# STM32WBA62 register map
File version: 1.1
CPU: CM33 r0p1, little endian, MPU, FPU, 4 interrupt priority bits
Registers are 32-bit, read-write, reset 0x0 unless marked. A register's access mark holds for its fields unless they carry their own. Offsets are from the block's base; [hi:lo] are bit positions; {n}, {i} and the like mark numbered series.

## FLASH — FLASH register block
Base 0x40022000
Same registers: SEC_FLASH 0x50022000
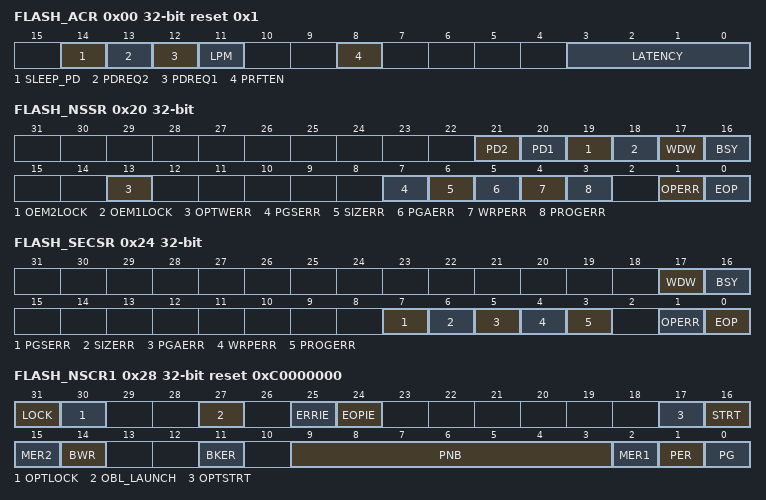
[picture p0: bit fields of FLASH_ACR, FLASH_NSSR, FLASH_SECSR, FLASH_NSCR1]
0x00 FLASH_ACR reset 0x1 — FLASH access control register
  [14] SLEEP_PD — Flash memory power-down mode during Sleep mode
    0=Flash in idle mode during Sleep mode; 1=Flash in power-down mode during Sleep mode
  [13] PDREQ2 — Bank 2 power-down mode request
    0=No request for bank 2 to enter power-down mode; 1=Bank 2 requested to enter power-down mode'
  [12] PDREQ1 — Bank 1 power-down mode request
    0=No request for bank 1 to enter power-down mode; 1=Bank 1 requested to enter power-down mode
  [11] LPM — Low-power read mode
    0=Flash not in low-power read mode; 1=Flash in low-power read mode
  [8] PRFTEN — Prefetch enable
    0=Prefetch disabled; 1=Prefetch enabled
  [3:0] LATENCY
    0=Zero wait state; 1=One wait state; 2=Two wait states; 15=Fifteen wait states
0x08 FLASH_NSKEYR wo — FLASH key register
  [31:0] NSKEY — Flash memory nonsecure key
0x0C FLASH_SECKEYR wo — FLASH secure key register
  [31:0] SECKEY — Flash memory secure key
0x10 FLASH_OPTKEYR wo — FLASH option key register
  [31:0] OPTKEY — Option byte key
0x18 FLASH_PDKEY1R wo — FLASH bank 1 power-down key register
  [31:0] PDKEY — Bank 1 power-down key
0x1C FLASH_PDKEY2R wo — FLASH bank 2 power-down key register
  [31:0] PDKEY — Bank 2 power-down key
0x20 FLASH_NSSR (reset mask 0xFFF0FFFF) — FLASH status register
  [21] PD2 ro — Bank 2 in power-down mode
  [20] PD1 ro — Bank 1 in power-down mode
  [19] OEM2LOCK ro — OEM2 key RDP lock
  [18] OEM1LOCK ro — OEM1 key RDP lock
  [17] WDW ro — nonsecure wait data to write
  [16] BSY ro — nonsecure busy
  [13] OPTWERR — Option write error
  [7] PGSERR — nonsecure programming sequence error
  [6] SIZERR — nonsecure size error
  [5] PGAERR — nonsecure programming alignment error
  [4] WRPERR — nonsecure write protection error
  [3] PROGERR — nonsecure programming error
  [1] OPERR — nonsecure operation error
  [0] EOP — nonsecure end of operation
0x24 FLASH_SECSR — FLASH secure status register
  [17] WDW ro — Secure wait data to write
  [16] BSY ro — Secure busy
  [7] PGSERR — Secure programming sequence error
  [6] SIZERR — Secure size error
  [5] PGAERR — Secure programming alignment error
  [4] WRPERR — Secure write protection error
  [3] PROGERR — Secure programming error
  [1] OPERR — Secure operation error
  [0] EOP — Secure end of operation
0x28 FLASH_NSCR1 reset 0xC0000000 — FLASH control register
  [31] LOCK — nonsecure lock
  [30] OPTLOCK — Option lock
  [27] OBL_LAUNCH — Force the option byte loading
    0=Option byte loading complete; 1=Option byte loading requested
  [25] ERRIE — nonsecure error interrupt enable
    0=nonsecure OPERR error interrupt disabled; 1=nonsecure OPERR error interrupt enabled
  [24] EOPIE — nonsecure end of operation interrupt enable
    0=nonsecure EOP Interrupt disabled; 1=nonsecure EOP Interrupt enabled
  [17] OPTSTRT — Options modification start
  [16] STRT — nonsecure operation start
  [15] MER2 — nonsecure flash bank 2 erase
  [14] BWR — nonsecure burst write programming mode
  [11] BKER — Bank selection for nonsecure page erase
    0=Bank 1 selected for nonsecure page erase; 1=Bank 2 selected for nonsecure page erase
  [9:3] PNB — nonsecure bank page number selection
    0=page 0; 1=page 1; 63=page 63; 127=page 127
  [2] MER1 — nonsecure flash bank 1 erase
  [1] PER — nonsecure page erase
    0=nonsecure page erase disabled; 1=nonsecure page erase enabled
  [0] PG — nonsecure programming
    0=nonsecure flash programming disabled; 1=nonsecure flash programming enabled
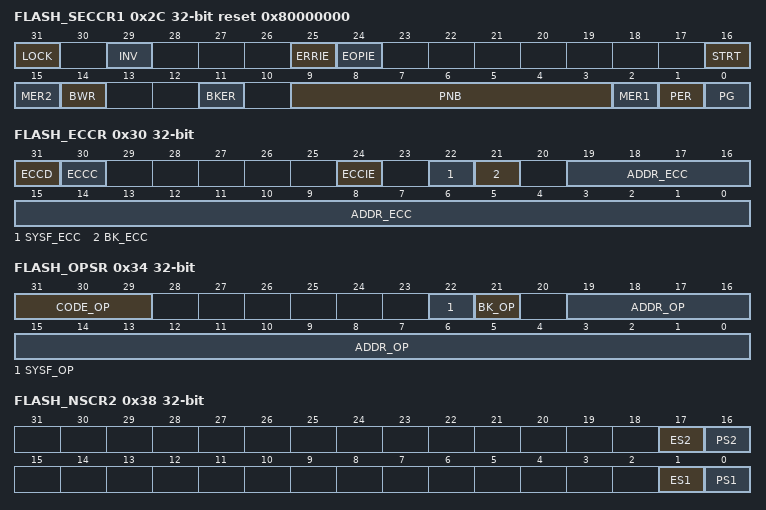
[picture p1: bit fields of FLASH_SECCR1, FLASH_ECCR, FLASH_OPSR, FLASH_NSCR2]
0x2C FLASH_SECCR1 reset 0x80000000 — FLASH secure control register
  [31] LOCK — Secure lock
  [29] INV — Flash memory security state invert
  [25] ERRIE — Secure error interrupt enable
    0=Secure OPERR error interrupt disabled; 1=Secure OPERR error interrupt enabled
  [24] EOPIE — Secure End of operation interrupt enable
    0=Secure EOP Interrupt disabled; 1=Secure EOP Interrupt enabled
  [16] STRT — Secure start
  [15] MER2 — Secure flash bank 2 erase
  [14] BWR — Secure burst write programming mode
  [11] BKER — Bank selection for secure page erase
    0=Bank 1 selected for secure page erase; 1=Bank 2 selected for secure page erase
  [9:3] PNB — Secure bank page number selection
    0=page 0; 1=page 1; 63=page 63; 127=page 127
  [2] MER1 — Secure flash bank 1 erase
  [1] PER — Secure page erase
    0=Secure page erase disabled; 1=Secure page erase enabled
  [0] PG — Secure programming
    0=Secure flash programming disabled; 1=Secure flash programming enabled
0x30 FLASH_ECCR — FLASH ECC register
  [31] ECCD — ECC detection
  [30] ECCC — ECC correction
  [24] ECCIE — ECC correction interrupt enable
    0=ECCC interrupt disabled; 1=ECCC interrupt enabled
  [22] SYSF_ECC ro — System flash memory ECC fail
  [21] BK_ECC ro — bank ECC fail
    0=Bank 1; 1=Bank 2
  [19:0] ADDR_ECC ro — ECC fail address
0x34 FLASH_OPSR ro (reset mask 0xF000000) — FLASH operation status register
  [31:29] CODE_OP — Flash memory operation code
    0=No flash operation interrupted by previous reset; 1=Single write operation interrupted; 2=Burst write operation interrupted; 3=Page erase operation interrupted; 4=Bank erase operation interrupted; 5=Mass erase operation interrupted; 6=Option change operation interrupted
  [22] SYSF_OP — Operation in system flash memory interrupted
  [21] BK_OP — Operation in bank interrupted
    0=Bank 1; 1=Bank 2
  [19:0] ADDR_OP — Interrupted operation address
0x38 FLASH_NSCR2 — FLASH control 2 register
  [17] ES2 — Bank 2 nonsecure erase suspend request
    0=Bank 2 nonsecure erase suspend disabled; 1=Bank 2 nonsecure erase suspend requested (enabled)
  [16] PS2 — Bank 2 nonsecure program suspend request
    0=Bank 2 nonsecure program suspend disabled; 1=Bank 2 nonsecure program suspend requested (enabled)
  [1] ES1 — Bank 1 nonsecure erase suspend request
    0=Bank 1 nonsecure erase suspend disabled; 1=Bank 1 nonsecure erase suspend requested (enabled)
  [0] PS1 — Bank 1 nonsecure program suspend request
    0=Bank 1 nonsecure program suspend disabled; 1=Bank 1 nonsecure program suspend requested (enabled)
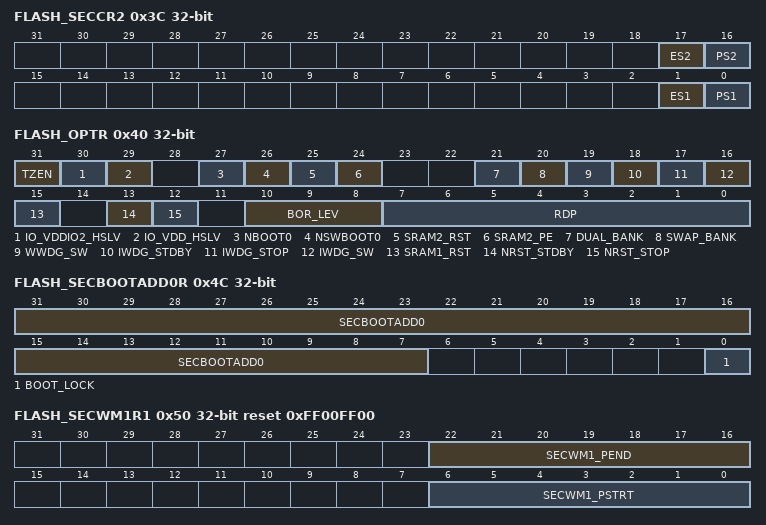
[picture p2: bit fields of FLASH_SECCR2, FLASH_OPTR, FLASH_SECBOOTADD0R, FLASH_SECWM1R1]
0x3C FLASH_SECCR2 — FLASH secure control 2 register
  [17] ES2 — Bank 2 secure erase suspend request
    0=Bank 2 secure erase suspend disabled; 1=Bank 2 secure erase suspend requested (enabled)
  [16] PS2 — Bank 2 secure program suspend request
    0=Bank 2 secure program suspend disabled; 1=Bank 2 secure program suspend requested (enabled)
  [1] ES1 — Bank 1 secure erase suspend request
    0=Bank 1 secure erase suspend disabled; 1=Bank 1 secure erase suspend requested (enabled)
  [0] PS1 — Bank 1 secure program suspend request
    0=Bank 1 secure program suspend disabled; 1=Bank 1 secure program suspend requested (enabled)
0x40 FLASH_OPTR reset not defined — FLASH option register
  [31] TZEN — Global TrustZone security enable
    0=Global TrustZone security disabled; 1=Global TrustZone security enabled
  [30] IO_VDDIO2_HSLV — High-speed IO at low Vless thansub DDIO2less than/sub voltage configuration
    0=High-speed IO at low Vless thansub DDIO2less than/sub voltage disabled; 1=High-speed IO at low Vless thansub DDIO2less than/sub voltage enabling in GPIO peripheral allowed (Vless thansub DDIO2less than/sub voltage must be below, refer to datasheet
  [29] IO_VDD_HSLV — High-speed IO at low Vless thansub DDless than/sub voltage configuration
    0=High-speed IO at low Vless thansub DDless than/sub voltage disabled; 1=High-speed IO at low Vless thansub DDless than/sub voltage enabling in GPIO peripheral allowed (Vless thansub DDless than/sub voltage must be below, refer to datasheet)
  [27] NBOOT0 — NBOOT0 option bit
    0=NBOOT0 = 0; 1=NBOOT0 = 1
  [26] NSWBOOT0 — Software BOOT0
    0=BOOT0 taken from the option bit NBOOT0; 1=BOOT0 taken from PH3/BOOT0 pin
  [25] SRAM2_RST — SRAM2 erase when system reset
    0=SRAM2 erased when a system reset occurs; 1=SRAM2 not erased when a system reset occurs
  [24] SRAM2_PE — SRAM2 parity check enable
    0=SRAM2 parity check enabled; 1=SRAM2 parity check disabled
  [21] DUAL_BANK — Dual-bank on 1-Mbyte flash memory
    0=Single-bank flash with contiguous addresses in bank 1; 1=Dual-bank flash with contiguous addresses
  [20] SWAP_BANK
    0=Banks not swapped, Main memory bank 1 base address offset 0, bank 2 base address offset 0x10 0000; 1=Banks swapped, Main memory bank 1 base address offset 0x10 0000, bank 2 base address offset 0
  [19] WWDG_SW — Window watchdog selection
    0=Hardware window watchdog selected; 1=Software window watchdog selected
  [18] IWDG_STDBY — Independent watchdog counter freeze in Standby mode
    0=Independent watchdog counter frozen in Standby mode; 1=Independent watchdog counter running in Standby mode
  [17] IWDG_STOP — Independent watchdog counter freeze in Stop mode
    0=Independent watchdog counter frozen in Stop mode; 1=Independent watchdog counter running in Stop mode
  [16] IWDG_SW — Independent watchdog enable selection
    0=Hardware mode, independent watchdog started automatically be hardware on reset selected; 1=Software mode, independent watchdog started by software command selected
  [15] SRAM1_RST — SRAM1 erase upon system reset
    0=SRAM1erased when a system reset occurs; 1=SRAM1 not erased when a system reset occurs
  [13] NRST_STDBY — Reset generation in Standby mode
    0=Reset generated when entering the Standby mode; 1=No reset generated when entering the Standby mode
  [12] NRST_STOP — Reset generation in Stop mode
    0=Reset generated when entering the Stop mode; 1=No reset generated when entering the Stop mode
  [10:8] BOR_LEV — BOR reset level
    0=BOR level 0 (reset level threshold around 1; {v}=BOR level {v} (reset level threshold around 2 (v=1..4)
  [7:0] RDP — Readout protection level
    170=Level 0 (readout protection not active); 85=Level 0; 204=Level 2 (chip readout protection active)
0x44 FLASH_NSBOOTADD0R reset 0xF (reset mask 0xF) — FLASH boot address 0 register
  [31:7] NSBOOTADD0 — nonsecure boot base address 0
0x48 FLASH_NSBOOTADD1R reset 0xF (reset mask 0xF) — FLASH boot address 1 register
  [31:7] NSBOOTADD1 — nonsecure boot address 1
0x4C FLASH_SECBOOTADD0R reset not defined — FLASH secure boot address 0 register
  [31:7] SECBOOTADD0 — Secure boot base address 0
  [0] BOOT_LOCK
0x50 FLASH_SECWM1R1 reset 0xFF00FF00 (reset mask 0xFF00FF00) — FLASH bank 1 secure watermark register 1
  [22:16] SECWM1_PEND — Bank 1 end page of secure area
  [6:0] SECWM1_PSTRT — Bank 1 start page of secure area
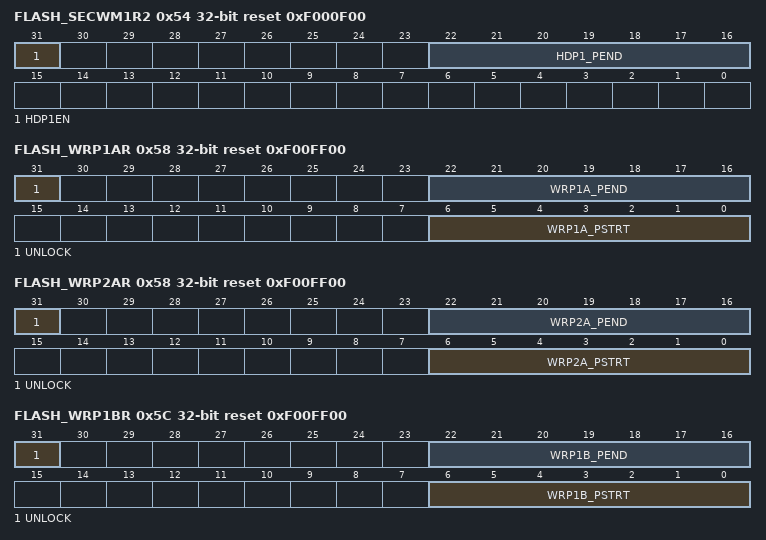
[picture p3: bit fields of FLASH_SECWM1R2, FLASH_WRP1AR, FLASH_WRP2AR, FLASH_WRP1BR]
0x54 FLASH_SECWM1R2 reset 0xF000F00 (reset mask 0xF000F00) — FLASH bank 1 secure watermark register 2
  [31] HDP1EN — Bank 1 secure Hide protection area enable
    0=No bank 1 secure HDP area; 1=Bank 1 secure HDP area enabled
  [22:16] HDP1_PEND — Bank 1 end page of secure hide protection area
0x58 FLASH_WRP1AR reset 0xF00FF00 (reset mask 0xF00FF00) — FLASH WRP bank 1 area A address register
  [31] UNLOCK — WPR bank 1 area A unlock
    0=WRP bank 1 area A start and end pages locked; 1=WRP bank 1 area A start and end pages unlocked
  [22:16] WRP1A_PEND — WPR bank 1 area A end page
  [6:0] WRP1A_PSTRT — WPR bank 1 area A start page
0x58 FLASH_WRP2AR reset 0xF00FF00 (reset mask 0xF00FF00) (alternate view of FLASH_WRP1AR) — FLASH WRP bank 2 area A address register
  [31] UNLOCK — WPR bank 2 area A unlock
    0=WRP bank 2 area A start and end pages locked; 1=WRP bank 2 area A start and end pages unlocked
  [22:16] WRP2A_PEND — WPR bank 2 area A end page
  [6:0] WRP2A_PSTRT — WPR bank 2 area A start page
0x5C FLASH_WRP1BR reset 0xF00FF00 (reset mask 0xF00FF00) — FLASH WRP bank 1 area B address register
  [31] UNLOCK — WPR area B unlock
    0=WRP bank 1 area B start and end pages locked; 1=WRP bank 1 area B start and end pages unlocked
  [22:16] WRP1B_PEND — WRP bank 1 area B end page
  [6:0] WRP1B_PSTRT — WRP bank 1 area B start page
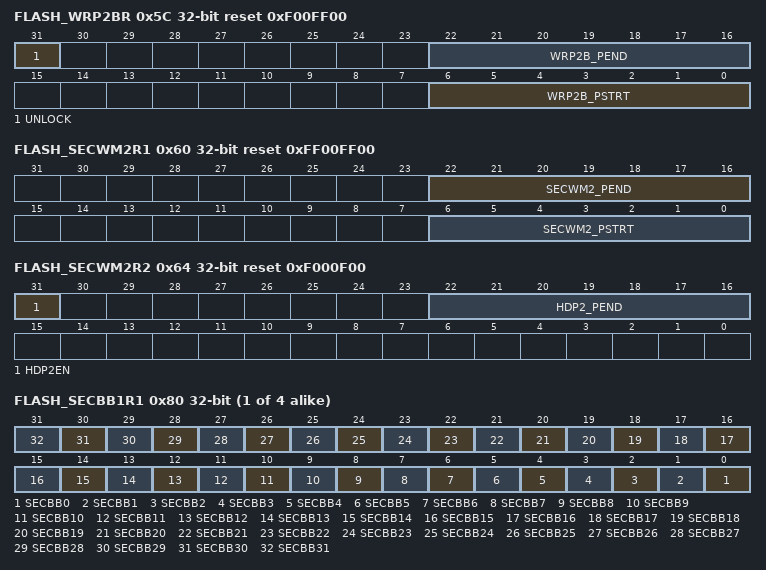
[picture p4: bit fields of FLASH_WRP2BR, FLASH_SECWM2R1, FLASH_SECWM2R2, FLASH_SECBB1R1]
0x5C FLASH_WRP2BR reset 0xF00FF00 (reset mask 0xF00FF00) (alternate view of FLASH_WRP1BR) — FLASH WRP bank 2 area B address register
  [31] UNLOCK — WPR bank 2 area B unlock
    0=WRP bank 2 area B start and end pages locked; 1=WRP bank 2 area B start and end pages unlocked
  [22:16] WRP2B_PEND — WRP bank 2 area B end page
  [6:0] WRP2B_PSTRT — WRP bank 2 area B start page
0x60 FLASH_SECWM2R1 reset 0xFF00FF00 (reset mask 0xFF00FF00) — FLASH bank 2 secure watermark register 1
  [22:16] SECWM2_PEND — End page of secure area
  [6:0] SECWM2_PSTRT — Start page of secure area
0x64 FLASH_SECWM2R2 reset 0xF000F00 (reset mask 0xF000F00) — FLASH bank 2 secure watermark register 2
  [31] HDP2EN — Bank 2 secure Hide protection area enable
    0=No bank 2 secure HDP area; 1=Bank 2 secure HDP area enabled
  [22:16] HDP2_PEND — Bank 2 end page of secure hide protection area
0x70 FLASH_OEM1KEYR1 wo — FLASH OEM1 key register 1
  [31:0] OEM1KEY — OEM1 key least significant bytes
0x74 FLASH_OEM1KEYR2 wo — FLASH OEM1 key register 2
  [31:0] OEM1KEY — OEM1 key most significant bytes
0x78 FLASH_OEM2KEYR1 wo — FLASH OEM2 key register 1
  [31:0] OEM2KEY — OEM2 key least significant bytes
0x7C FLASH_OEM2KEYR2 wo — FLASH OEM2 key register 2
  [31:0] OEM2KEY — OEM2 key most significant bytes
{0x7C+4i} FLASH_SECBB1R{i} (i=1..4) — FLASH bank 1 secure block based register {i}
  [all] fields
    0=Page (32 x (x - 1) + y) in flash bank 1 not block-based secure; 1=Page (32 x (x - 1) + y) in flash bank 1 block-based secure
  [n] SECBB{n} (n=0..31) — Bank 1 page secure/nonsecure attribution
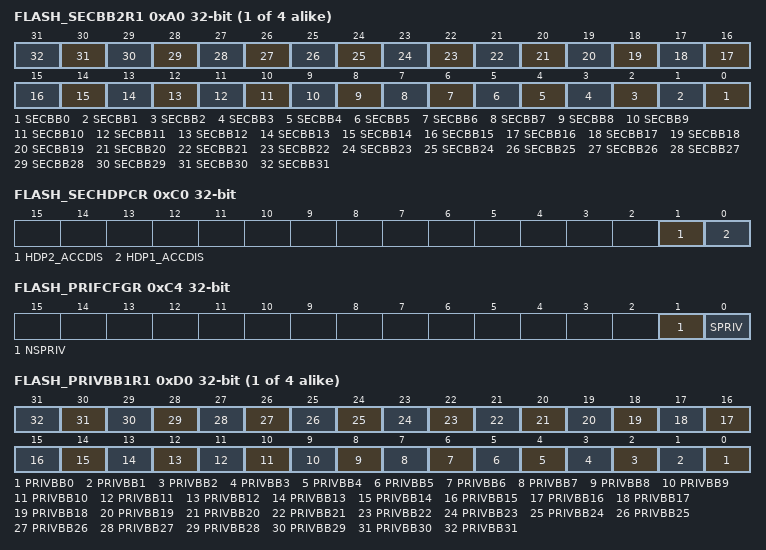
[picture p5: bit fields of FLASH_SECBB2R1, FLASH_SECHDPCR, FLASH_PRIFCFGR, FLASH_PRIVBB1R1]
{0x9C+4i} FLASH_SECBB2R{i} (i=1..4) — FLASH bank 2 secure block based register {i}
  [all] fields
    0=Page (32 x (x - 1) + y) in flash bank 2 not block-based secure; 1=Page (32 x (x - 1) + y) in flash bank 2 block-based secure
  [n] SECBB{n} (n=0..31) — Bank 2 page secure/nonsecure attribution
0xC0 FLASH_SECHDPCR — FLASH secure HDP control register
  [1] HDP2_ACCDIS — Bank 2 secure HDP area access disable
    0=Access to bank 2 secure HDP area granted; 1=Access to bank 2 secure HDP area denied (SECWMxRy option bytes modification blocked, refer to Rules for modifying specific option bytes)
  [0] HDP1_ACCDIS — Bank 1 secure HDP area access disable
    0=Access to bank 1 secure HDP area granted; 1=Access to bank 1 secure HDP area denied (SECWMxRy option bytes modification blocked, refer to Rules for modifying specific option bytes)
0xC4 FLASH_PRIFCFGR — FLASH privilege configuration register
  [1] NSPRIV — Privileged protection for nonsecure registers
    0=nonsecure flash registers can be read and written by privileged or unprivileged access; 1=nonsecure flash registers can be read and written by privileged access only
  [0] SPRIV — Privileged protection for secure registers
    0=Secure flash registers can be read and written by privileged or unprivileged access; 1=Secure flash registers can be read and written by privileged access only
{0xCC+4i} FLASH_PRIVBB1R{i} (i=1..4) — FLASH bank 1 privilege block based register {i}
  [all] fields
    0=Page (32 x (x - 1) + y) in flash bank 1 accessible by unprivileged access; 1=Page (32 x (x - 1) + y) in flash bank 1 only accessible by privileged access
  [n] PRIVBB{n} (n=0..31) — Bank 1 page privileged/unprivileged attribution
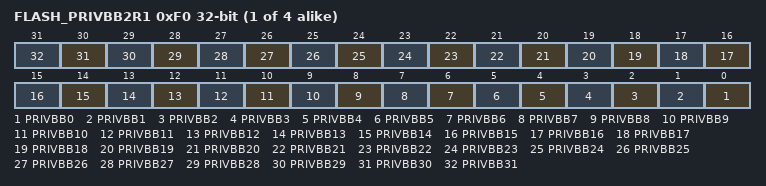
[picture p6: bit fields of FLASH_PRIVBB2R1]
{0xEC+4i} FLASH_PRIVBB2R{i} (i=1..4) — FLASH bank 2 privilege block based register {i}
  [all] fields
    0=Page (32 x (x - 1) + y) in flash bank 2 accessible by unprivileged access; 1=Page (32 x (x - 1) + y) in flash bank 2 only accessible by privileged access
  [n] PRIVBB{n} (n=0..31) — Bank 2 page privileged/unprivileged attribution
